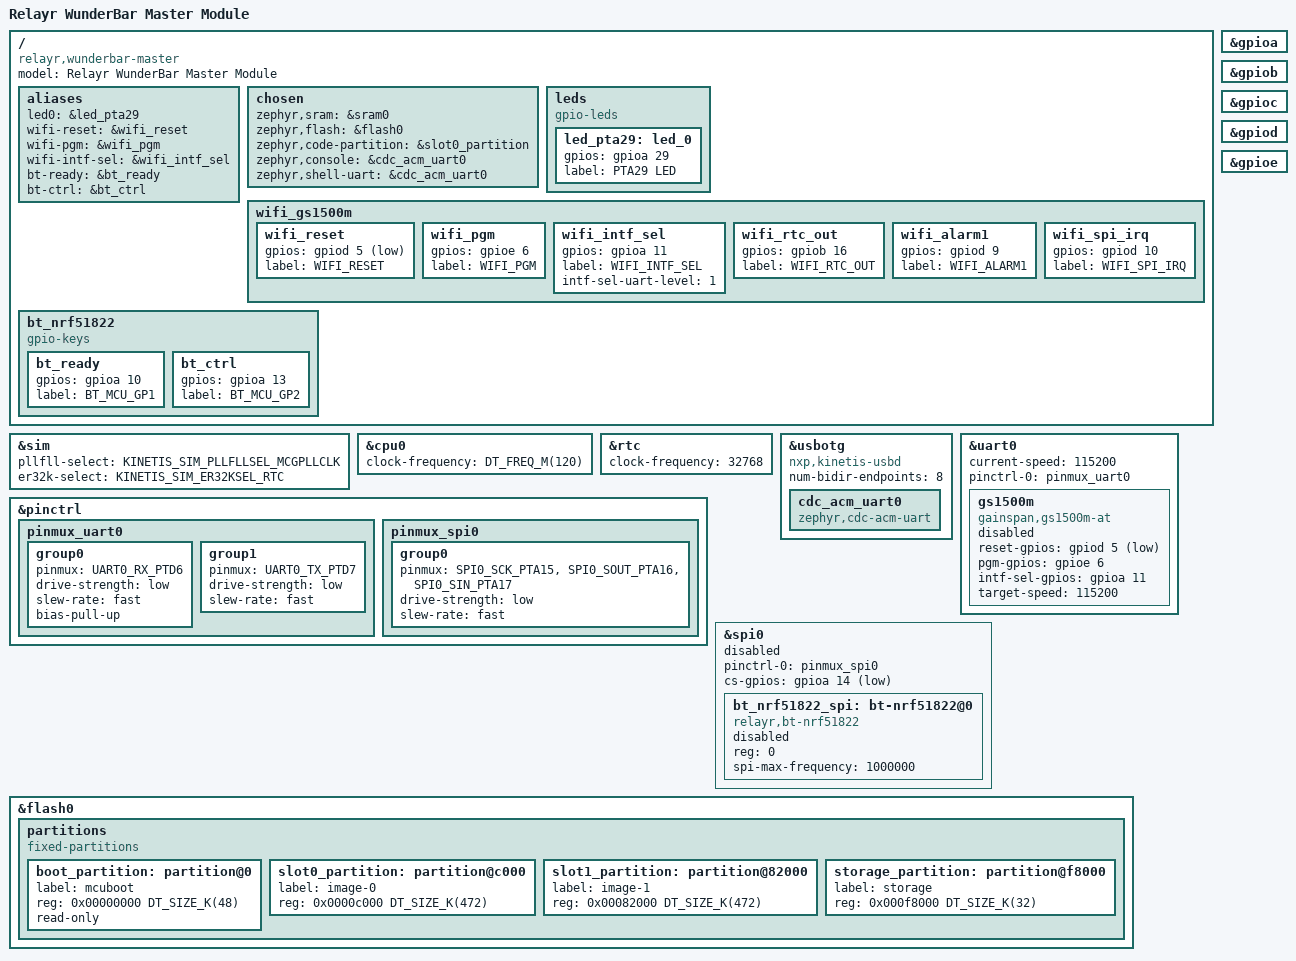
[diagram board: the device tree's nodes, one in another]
/*
 * Copyright (c) 2026
 * SPDX-License-Identifier: Apache-2.0
 *
 * Relayr WunderBar master module — MK24FN1M0VDC12.
 *
 * Clock sources (from schematic):
 *   - Y1  12 MHz on EXTAL0/XTAL0 with C17/C18 = 12 pF
 *   - X8  32.768 kHz on EXTAL32/XTAL32 with C104/C105 = 12 pF
 *
 * Zephyr SoC support uses the MK64F12 tree (superset / shared Kinetis K
 * enablement). Target core clock is 120 MHz via MCG PEE.
 *
 * GS1500M WiFi (UART AT @ 115200): PTD6/PTD7 UART0, PTD5 reset, PTE6 PGM,
 * PTA11 INTF_SEL. SPI PTD10–14 reserved / unused by AT path.
 */

/dts-v1/;

#include <nxp/kinetis/nxp_k6x.dtsi>
#include <nxp/kinetis/MK24FN1M0VDC12-pinctrl.h>
#include <zephyr/dt-bindings/gpio/gpio.h>
#include <freq.h>

/ {
	model = "Relayr WunderBar Master Module";
	compatible = "relayr,wunderbar-master", "nxp,mk24f12", "nxp,k6x";

	aliases {
		led0 = &led_pta29;
		wifi-reset = &wifi_reset;
		wifi-pgm = &wifi_pgm;
		wifi-intf-sel = &wifi_intf_sel;
		bt-ready = &bt_ready;
		bt-ctrl = &bt_ctrl;
	};

	chosen {
		zephyr,sram = &sram0;
		zephyr,flash = &flash0;
		zephyr,code-partition = &slot0_partition;
		zephyr,console = &cdc_acm_uart0;
		zephyr,shell-uart = &cdc_acm_uart0;
	};

	leds {
		compatible = "gpio-leds";

		/* User LED on PTA29 (GPIOA pin 29). Active-high assumed;
		 * change to GPIO_ACTIVE_LOW if the LED sinks to ground through
		 * an active-low buffer on your PCB revision.
		 */
		led_pta29: led_0 {
			gpios = <&gpioa 29 GPIO_ACTIVE_HIGH>;
			label = "PTA29 LED";
		};
	};

	/*
	 * GS1500M control GPIOs. INTF_SEL UART polarity defaults to logical 1
	 * (GainSpan UART=high / SPI=low; see GS_INTF_SEL_UART_LEVEL).
	 * SPI PTD10–14 reserved / unused by AT.
	 */
	wifi_gs1500m {
		wifi_reset: wifi_reset {
			gpios = <&gpiod 5 GPIO_ACTIVE_LOW>;
			label = "WIFI_RESET";
		};

		wifi_pgm: wifi_pgm {
			gpios = <&gpioe 6 GPIO_ACTIVE_HIGH>;
			label = "WIFI_PGM";
		};

		wifi_intf_sel: wifi_intf_sel {
			gpios = <&gpioa 11 GPIO_ACTIVE_HIGH>;
			label = "WIFI_INTF_SEL";
			intf-sel-uart-level = <1>;
		};

		wifi_rtc_out: wifi_rtc_out {
			gpios = <&gpiob 16 GPIO_ACTIVE_HIGH>;
			label = "WIFI_RTC_OUT";
		};

		wifi_alarm1: wifi_alarm1 {
			gpios = <&gpiod 9 GPIO_ACTIVE_HIGH>;
			label = "WIFI_ALARM1";
		};

		wifi_spi_irq: wifi_spi_irq {
			gpios = <&gpiod 10 GPIO_ACTIVE_HIGH>;
			label = "WIFI_SPI_IRQ";
		};
	};

	/*
	 * nRF51822 host link: SPI0 on PTA14–17 + GP1/GP2 handshake.
	 * CS driven as GPIO (cs-gpios); SCK/SOUT/SIN via DSPI ALT2.
	 */
	bt_nrf51822 {
		compatible = "gpio-keys";

		bt_ready: bt_ready {
			gpios = <&gpioa 10 GPIO_ACTIVE_HIGH>;
			label = "BT_MCU_GP1";
		};

		bt_ctrl: bt_ctrl {
			gpios = <&gpioa 13 GPIO_ACTIVE_HIGH>;
			label = "BT_MCU_GP2";
		};
	};
};

&sim {
	pllfll-select = <KINETIS_SIM_PLLFLLSEL_MCGPLLCLK>;
	er32k-select = <KINETIS_SIM_ER32KSEL_RTC>;
};

&cpu0 {
	clock-frequency = <DT_FREQ_M(120)>;
};

&rtc {
	status = "okay";
	clock-frequency = <32768>;
};

zephyr_udc0: &usbotg {
	compatible = "nxp,kinetis-usbd";
	status = "okay";
	num-bidir-endpoints = <8>;

	cdc_acm_uart0: cdc_acm_uart0 {
		compatible = "zephyr,cdc-acm-uart";
	};
};

&pinctrl {
	pinmux_uart0: pinmux_uart0 {
		group0 {
			pinmux = <UART0_RX_PTD6>;
			drive-strength = "low";
			slew-rate = "fast";
			bias-pull-up;
		};
		group1 {
			pinmux = <UART0_TX_PTD7>;
			drive-strength = "low";
			slew-rate = "fast";
		};
	};

	/* BT SPI0: PTA15 SCK, PTA16 SOUT (MOSI), PTA17 SIN (MISO).
	 * PTA14 CS is GPIO via cs-gpios (not PCS0 mux).
	 */
	pinmux_spi0: pinmux_spi0 {
		group0 {
			pinmux = <SPI0_SCK_PTA15>,
				 <SPI0_SOUT_PTA16>,
				 <SPI0_SIN_PTA17>;
			drive-strength = "low";
			slew-rate = "fast";
		};
	};
};

&uart0 {
	status = "okay";
	current-speed = <115200>;
	pinctrl-0 = <&pinmux_uart0>;
	pinctrl-names = "default";

	/*
	 * GainSpan GS1500M Serial2WiFi offload (wifi_mgmt). Control GPIOs
	 * match board wifi_* nodes / PE bring-up.
	 */
	gs1500m: gs1500m {
		compatible = "gainspan,gs1500m-at";
		/* Enabled by apps/zephyr_wifi overlay; keep off for blinky. */
		status = "disabled";
		reset-gpios = <&gpiod 5 GPIO_ACTIVE_LOW>;
		pgm-gpios = <&gpioe 6 GPIO_ACTIVE_HIGH>;
		intf-sel-gpios = <&gpioa 11 GPIO_ACTIVE_HIGH>;
		target-speed = <115200>;
	};
};

/*
 * SPI0 ↔ nRF51822 (BT_SPI_*). Enabled by apps/zephyr_bt_host overlay so
 * blinky/wifi builds stay lean.
 */
&spi0 {
	status = "disabled";
	pinctrl-0 = <&pinmux_spi0>;
	pinctrl-names = "default";
	cs-gpios = <&gpioa 14 GPIO_ACTIVE_LOW>;

	bt_nrf51822_spi: bt-nrf51822@0 {
		compatible = "relayr,bt-nrf51822";
		reg = <0>;
		spi-max-frequency = <1000000>;
		status = "disabled";
	};
};

&gpioa {
	status = "okay";
};

&gpiob {
	status = "okay";
};

&gpioc {
	status = "okay";
};

&gpiod {
	status = "okay";
};

&gpioe {
	status = "okay";
};

&flash0 {
	partitions {
		compatible = "fixed-partitions";
		#address-cells = <1>;
		#size-cells = <1>;

		boot_partition: partition@0 {
			label = "mcuboot";
			reg = <0x00000000 DT_SIZE_K(48)>;
			read-only;
		};

		slot0_partition: partition@c000 {
			label = "image-0";
			reg = <0x0000c000 DT_SIZE_K(472)>;
		};

		slot1_partition: partition@82000 {
			label = "image-1";
			reg = <0x00082000 DT_SIZE_K(472)>;
		};

		storage_partition: partition@f8000 {
			label = "storage";
			reg = <0x000f8000 DT_SIZE_K(32)>;
		};
	};
};
